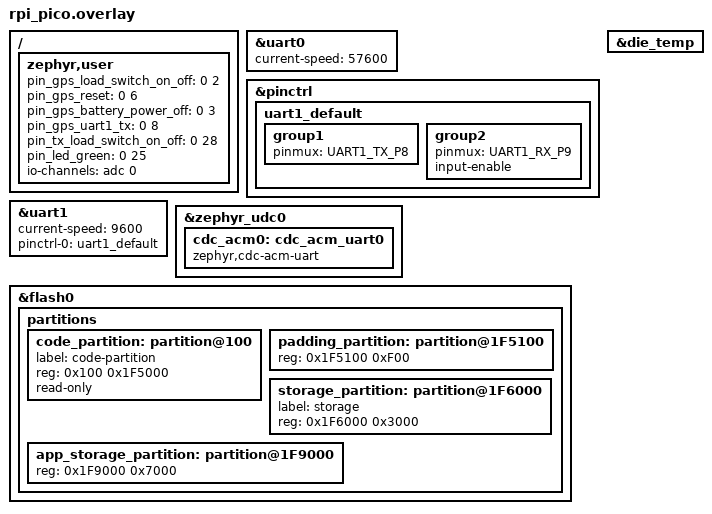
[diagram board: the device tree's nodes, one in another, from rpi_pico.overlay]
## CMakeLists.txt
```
cmake_minimum_required(VERSION 3.13)

# Locate LibPico and pull in initial cmake work
set(LIB_PICO "${CMAKE_CURRENT_SOURCE_DIR}/../../lib")
include(${LIB_PICO}/cmake.preproject.cmake)

# Primary configuration for this project
set(PROJECT_NAME "Traquito")
set(APP_BUILD_VERSION "2024-03-19 16:04:22")
set(PICO_BOARD_ACTUAL "pico")

# Final cmake work
include(${LIB_PICO}/cmake.app.after.cmake)
```

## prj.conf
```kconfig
#####################################################################
# set up project to use c++17 and useful libs/stl
#####################################################################
CONFIG_CPP=y
CONFIG_REQUIRES_FULL_LIBCPP=y
CONFIG_CPP_MAIN=y
CONFIG_STD_CPP20=y
CONFIG_NEWLIB_LIBC_FLOAT_PRINTF=y
CONFIG_CBPRINTF_FP_SUPPORT=y


#####################################################################
# maximum debugging - my code, kernel, everything
#####################################################################
CONFIG_DEBUG_OPTIMIZATIONS=y
CONFIG_DEBUG=y
CONFIG_DEBUG_THREAD_INFO=y
CONFIG_EXCEPTION_STACK_TRACE=y
CONFIG_DEBUG_INFO=y


#####################################################################
# Power Management
#####################################################################


# enabled by default but let's be explicit
# CONFIG_PM=y

# collect stats for this module
# CONFIG_PM_STATS=y

# enable using device driver hooks to be called when
# going in to or out of suspend
# CONFIG_PM_DEVICE=y
# allow individual devices to be suspended/resumed regardless
# of the rest of the system state
# CONFIG_PM_DEVICE_RUNTIME=y
# use the preferred method of managing power, it is handled
# continuously by components close to the resources and
# who are power aware.  resources are meant to be kept
# in the lowest appropriate power state such that
# when a pm_system_suspend() is invoked, it is performed
# more quickly
# CONFIG_PM_DEVICE_RUNTIME_EXCLUSIVE=n



# Allow custom hooks to decide policy each idle period (PowerManager)
# Uncommenting this, and the CMakeLists including Power Manager gets
# the tests going again, but moving on for now.
# CONFIG_PM_POLICY_CUSTOM=y



#####################################################################
# PICO specific HWINFO
#####################################################################

# https://github.com/zephyrproject-rtos/zephyr/pull/54290
# https://github.com/zephyrproject-rtos/zephyr/commit/480ff022bde2d450372bf5339f5ed06453ff9176

# seemingly not ready yet, so commenting out for now

# CONFIG_RP2_BINARY_INFO=y

# CONFIG_RP2_BINARY_INFO_RP_PROGRAM_NAME_OVERRIDE=y
# CONFIG_RP2_BINARY_INFO_RP_PROGRAM_NAME="Traquito"

# CONFIG_RP2_BINARY_INFO_RP_PROGRAM_DESCRIPTION_OVERRIDE=y
# CONFIG_RP2_BINARY_INFO_RP_PROGRAM_DESCRIPTION="Traquito"

# CONFIG_RP2_BINARY_INFO_RP_PROGRAM_URL_OVERRIDE=y
# CONFIG_RP2_BINARY_INFO_RP_PROGRAM_URL="https://traquito.github.io"


#####################################################################
# PICO features
#####################################################################

CONFIG_RPI_PICO_TEMP=y


#####################################################################
# kernel features
#####################################################################

# kernel pipes
CONFIG_PIPES=y


#####################################################################
# main thread
#####################################################################

CONFIG_MAIN_STACK_SIZE=4096


#####################################################################
# system features
#####################################################################

# Enable rebooting by code
CONFIG_REBOOT=y

# monitor high-water mark on stack by placing known-values in stack
# buffer before running
CONFIG_INIT_STACKS=y

# support random number generation
CONFIG_ENTROPY_GENERATOR=y

# Support checking the temperature
CONFIG_SENSOR=y

# Enable I2C/TWI
# https://docs.zephyrproject.org/latest/hardware/peripherals/i2c.html
CONFIG_I2C=y


# watchdog control
CONFIG_WATCHDOG=y
CONFIG_WDT_DISABLE_AT_BOOT=y


# enable access to flash storage
CONFIG_FLASH=y
CONFIG_FLASH_PAGE_LAYOUT=y
CONFIG_NVS=y
CONFIG_MPU_ALLOW_FLASH_WRITE=y


# ADC
CONFIG_ADC=y

# enable stats collection per-module
CONFIG_STATS=y


CONFIG_HWINFO=y

#####################################################################
# Set up interfacing
#####################################################################

# no startup banner
CONFIG_BOOT_BANNER=n

# I want serial enabled in general
CONFIG_SERIAL=y
CONFIG_UART_INTERRUPT_DRIVEN=y
CONFIG_UART_LINE_CTRL=y

# I want logging to function
CONFIG_LOG=y

# I want to use the serial interface for logging
# but when I enable shell, this makes printf'd material come out twice,
# once normally, and another time with the shell prefix.
# so I'm disabling it for now.
CONFIG_LOG_BACKEND_UART=y
CONFIG_LOG_BACKEND_SWO=n

# I want synchronous logging (no queue and print later)
CONFIG_LOG_MODE_IMMEDIATE=y

# I want to be able to influnce what gets logged at runtime (via shell)
CONFIG_LOG_RUNTIME_FILTERING=y

# I want the default to be that every module prints all levels
# 0 = off
# 1 = error
# 2 = error and warning
# 3 = error and warning and info
# 4 = error and warning and info and debug
CONFIG_LOG_DEFAULT_LEVEL=3

# show function name in output
CONFIG_LOG_FUNC_NAME_PREFIX_ERR=y
CONFIG_LOG_FUNC_NAME_PREFIX_WRN=y
CONFIG_LOG_FUNC_NAME_PREFIX_INF=y
CONFIG_LOG_FUNC_NAME_PREFIX_DBG=y

# color it
CONFIG_LOG_BACKEND_SHOW_COLOR=y

# redirect printk to the log
# I am disabling this, because when shell enabled, prink output was
# prefixed with shell.  now I see it on serial with no prefix.
#CONFIG_LOG_PRINTK=y



# ##### Shell #####

# # I want the shell interface to operate
CONFIG_SHELL=y




#####################################################################
# set up stats
#####################################################################
CONFIG_THREAD_RUNTIME_STATS=y




#####################################################################
# set up pwm
#####################################################################
CONFIG_PWM=y


#####################################################################
# set up usb
#####################################################################

CONFIG_USB_DEVICE_DRIVER=y
CONFIG_USB_DEVICE_STACK=y

#
# USB Device Identification
#
CONFIG_USB_DEVICE_SN="0123456789ABCDEF"
CONFIG_USB_DEVICE_VID=0x2FE3
CONFIG_USB_DEVICE_PID=0x0008
CONFIG_USB_DEVICE_MANUFACTURER="Traquito"
CONFIG_USB_DEVICE_PRODUCT="Traquito"

#
# Serial via USB
#
CONFIG_USB_CDC_ACM=y
# makes windows 7 work
CONFIG_CDC_ACM_IAD=y

# use this instead?  NRFX was 2048, this defaults to 1024
# CONFIG_USB_WORKQUEUE_STACK_SIZE=








# CONFIG_USB_MASS_STORAGE=y
# # must be 8 chars
# CONFIG_MASS_STORAGE_INQ_VENDOR_ID="ABCDEFGH"
# # must be 16 chars
# CONFIG_MASS_STORAGE_INQ_PRODUCT_ID="0123456789ABCDEF"
# CONFIG_MASS_STORAGE_STACK_SIZE=2048


# CONFIG_DISK_DRIVER_RAM=y
# CONFIG_FILE_SYSTEM=y
# CONFIG_FAT_FILESYSTEM_ELM=y
# CONFIG_DISK_RAM_VOLUME_SIZE=2



# CONFIG_DISK_ACCESS=y
# CONFIG_DISK_DRIVERS=y
# CONFIG_FS_FATFS_READ_ONLY=n
# CONFIG_FS_FATFS_MOUNT_MKFS=y

# CONFIG_NRF_APPROTECT_LOCK=
# CONFIG_NRF_APPROTECT_USE_UICR=
# CONFIG_NRF_APPROTECT_USER_HANDLING=


#####################################################################
# set up disk
#####################################################################

# CONFIG_DISK_ACCESS=y
# CONFIG_DISK_DRIVERS=y


# CONFIG_FLASH=y
# CONFIG_DISK_DRIVER_FLASH=y


# CONFIG_FLASH_MAP=y
# CONFIG_FLASH_PAGE_LAYOUT=y
# CONFIG_MPU_ALLOW_FLASH_WRITE=y


# CONFIG_FILE_SYSTEM=y
# CONFIG_FAT_FILESYSTEM_ELM=y
# CONFIG_FS_FATFS_READ_ONLY=n
# CONFIG_FS_FATFS_MOUNT_MKFS=y




# #####################################################################
# # set multi-protocol service layer (multiple radio protocol support)
# #####################################################################
# # enable multi-protocol service layer (doesn't work with CONFIG_BT_LL_SW_SPLIT seemingly)
# CONFIG_MPSL=y
# # max sessions MPSL will support
# # 1 for BLE
# # 1 for ESB
# # 2 for MPSL shell testing
# # 1 for ESB shell testing
# CONFIG_MPSL_TIMESLOT_SESSION_COUNT=5
# # let's see during dev
# CONFIG_MPSL_LOG_LEVEL_DBG=y
# # allow myself to catch assert errors in my own code (and still die)
# CONFIG_MPSL_ASSERT_HANDLER=y






#####################################################################
# set up ble
#####################################################################
# CONFIG_SYSTEM_WORKQUEUE_STACK_SIZE=2048
# CONFIG_BT_RX_STACK_SIZE=4096
# CONFIG_MAIN_STACK_SIZE=6114
# CONFIG_BT=y
# CONFIG_BT_HCI=y
# CONFIG_BT_CTLR=y
# # Use the zephyr BLE implementation instead of the SoftDevice from Nordic
# # CONFIG_BT_LL_SW_SPLIT=y


# # use extended advertising
# CONFIG_BT_EXT_ADV=y
# # support this many advertising sets
# CONFIG_BT_EXT_ADV_MAX_ADV_SET=4


# CONFIG_BT_PERIPHERAL=y
# CONFIG_BT_CENTRAL=y
# CONFIG_BT_BROADCASTER=y
# CONFIG_BT_OBSERVER=y

# # Enable Security Manager Protocol (SMP), making it possible to pair devices over LE
# CONFIG_BT_SMP=y

# # allow me to set the code to show to users on their device via bt_passkey_set()
# CONFIG_BT_FIXED_PASSKEY=y

# # let me see more details about the other side of the connection
# CONFIG_BT_REMOTE_INFO=y

# # let me change and see changes to the PHY layer
# CONFIG_BT_USER_PHY_UPDATE=y

# # let me change and see changes to the data length (MTU?)
# CONFIG_BT_USER_DATA_LEN_UPDATE=y

# # let me express preferences for phy modulation
# CONFIG_BT_CTLR_PHY_CODED=y
# # CONFIG_BT_HCI_VS_EXT=y
# # CONFIG_BT_PHY_UPDATE=y

# # let me change (my) and measure (their) transmit power levels
# CONFIG_BT_CTLR_CONN_RSSI=y
# # CONFIG_BT_CTLR_ADVANCED_FEATURES=y    ; # triggers warning, needed?
# CONFIG_BT_CTLR_TX_PWR_DYNAMIC_CONTROL=y
# # ?
# # CONFIG_BT_TPS=y



# #####################################################################
# # set up ESB (extended shock burst)
# #####################################################################
# CONFIG_ESB=y
# CONFIG_NCS_SAMPLES_DEFAULTS=y
# CONFIG_ESB_MAX_PAYLOAD_LENGTH=252
# CONFIG_ESB_RX_FIFO_SIZE=1
# CONFIG_ESB_TX_FIFO_SIZE=1



# fat frames
# https://devzone.nordicsemi.com/f/nordic-q-a/84226/increasing-ble-mtu-data-length-for-notifications-on-ncs-v1-8
# https://github.com/zephyrproject-rtos/zephyr/issues/25648
# Uncoded LE Data Packet Format:
#
# | Preamble | Access  |                           PDU (2 to 257 bytes)                         |   CRC   |
# |          | Address | LL Header |       Link Layer PDU (0 to 251 bytes)           |    MIC   |         |
# |          |         |           | L2CAP Header |      L2CAP PDU (0-247 bytes)     | Optional |         |
# |          |         |           |              |    ATT Header    |  ATT Payload  |          |         |
# |          |         |           |              | OpCode | Handle  |               |          |         |
# |  1 byte  | 4 bytes |  2 bytes  |   4 bytes    | 1 byte | 2 bytes | 0 - 244 bytes | 4 bytes  | 3 bytes |
#
# L2CAP can be larger than 247 bytes, but will be split across multiple LL packets as a result.
# ATT payloads can be larger than 244 bytes, but will be split across multiple LL packets as a result.
# 
#
# Kconfig Symbols:
#     CONFIG_BT_CTLR_DATA_LENGTH_MAX : Maximum payload size of the Link Layer PDU
#     CONFIG_BT_BUF_ACL_TX_SIZE      : Maximum L2CAP PDU is limited to this value - 4
#     CONFIG_BT_BUF_ACL_RX_SIZE      : Maximum L2CAP PDU is limited to this value - 4
#     CONFIG_BT_L2CAP_TX_MTU         : Maximum L2CAP PDU size for transmission
# CONFIG_BT_BUF_ACL_RX_SIZE=251
# CONFIG_BT_BUF_ACL_TX_SIZE=251
# CONFIG_BT_L2CAP_TX_MTU=247
# CONFIG_BT_CTLR_DATA_LENGTH_MAX=251
# # CONFIG_BT_GATT_AUTO_UPDATE_MTU=


# CONFIG_BT_GATT_DYNAMIC_DB=y
# CONFIG_BT_DEVICE_APPEARANCE_DYNAMIC=y
# CONFIG_BT_DEVICE_NAME_DYNAMIC=y


# # unsure these
# #CONFIG_BT_EXT_ADV=y


# # settings subsystem required as well for bluetooth libs (for bonding)
# CONFIG_BT_SETTINGS=y
# CONFIG_FLASH=y
# CONFIG_FLASH_PAGE_LAYOUT=y
# CONFIG_FLASH_MAP=y
# CONFIG_NVS=y
# CONFIG_SETTINGS=y

# # major memory hog, ~2k per connection (wtf)
# CONFIG_BT_MAX_CONN=20


#####################################################################
# allow access to flash for read/write (non-volatile memory store)
#####################################################################

# CONFIG_MPU_ALLOW_FLASH_WRITE=y

# CONFIG_FLASH=y
# CONFIG_FLASH_MAP=y
# CONFIG_FLASH_PAGE_LAYOUT=y

# CONFIG_FILE_SYSTEM=y
# CONFIG_FILE_SYSTEM_LITTLEFS=y
```

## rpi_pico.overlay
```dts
/////////////////////////////////////////////////////////////////////
// App-specific settings
/////////////////////////////////////////////////////////////////////

/ {
    zephyr,user {
        pin_gps_load_switch_on_off = <0 2>;
        pin_gps_reset              = <0 6>;
        pin_gps_battery_power_off  = <0 3>;
        pin_gps_uart1_tx           = <0 8>;

        pin_tx_load_switch_on_off = <0 28>;
        
        pin_led_green = <0 25>;
    };
};



/////////////////////////////////////////////////////////////////////
// UART0
/////////////////////////////////////////////////////////////////////

&uart0 {
    // current-speed = <76800>;    // 48MHz handles it no prob
    current-speed = <57600>;    // 48MHz handles it no prob, probably higher too
    // current-speed = <38400>;    // 12MHz can not handle it
    // current-speed = <19200>;    // 12MHz can not handle it
    // current-speed = <9600>;
};




/////////////////////////////////////////////////////////////////////
// UART1
/////////////////////////////////////////////////////////////////////

&pinctrl {
	uart1_default: uart1_default {
		group1 {
			pinmux = <UART1_TX_P8>;
		};
		group2 {
            pinmux = <UART1_RX_P9>;
			input-enable;
		};
	};
};

&uart1 {
    current-speed = <9600>;
	status = "okay";
	pinctrl-0 = <&uart1_default>;
	pinctrl-names = "default";
};


/////////////////////////////////////////////////////////////////////
// UART USB
/////////////////////////////////////////////////////////////////////

&zephyr_udc0 {
    cdc_acm0: cdc_acm_uart0 {
        compatible = "zephyr,cdc-acm-uart";
	};
};


/////////////////////////////////////////////////////////////////////
// ADC
/////////////////////////////////////////////////////////////////////

// ADC already enabled on all 4 channels
// CH0 = GP26
// CH1 = GP27
// CH2 = GP28
// CH3 = GP29       // VSYS/3
// CH4 = <internal> // temperature sensor

/ {
	zephyr,user {
		io-channels = <&adc 0>;
	};
};



/////////////////////////////////////////////////////////////////////
// Temperature sensor (internal)
/////////////////////////////////////////////////////////////////////

&die_temp {
    status = "okay";
};

/////////////////////////////////////////////////////////////////////
// Flash Partitions
/////////////////////////////////////////////////////////////////////

/delete-node/ &code_partition;

&flash0 {
	partitions {
        // we want to reserve space for the zerphyr-convention of a "storage"
        // partition existing, since a number of zephyr libs beyond my control
        // expect it to exist.
        //
        // we also want to have app-specific storage.
        //
        // the storage partition should be 8192 bytes
        // on nordic this was 3 pages, not sure yet on pico
        //
        // the app storage partition should be 24,576 bytes
        // on noridc this was 7 pages, not sure yet on pico

        // we will have to override the pico-defined size of the
        // code partition.
        // 
        // on nordic, the flash pages were on 0x1000 boundaries.
        // that may not be the case here.  but since we have a ton
        // of storage, I'll play it safe and have a gap fill between
        // the code and the partition so they align to the 0x1000
        // boundaries

        // calculations:
        // https://docs.google.com/spreadsheets/d/1JafSN7NNXzIZdNnoIFAYexfTvMJzwK_n4mVGBEJF45I/edit#gid=0

		code_partition: partition@100 {
			label = "code-partition";
			reg = <0x100 0x1F5000>;
			read-only;
		};
        
		padding_partition: partition@1F5100 {
            reg = <0x1F5100 0xF00>;
            /delete-property/ read-only;
		};
        
		storage_partition: partition@1F6000 {
            label = "storage";
			reg = <0x1F6000 0x3000>;
            /delete-property/ read-only;
		};
        
		app_storage_partition: partition@1F9000 {
            reg = <0x1F9000 0x7000>;
            /delete-property/ read-only;
		};
	};
};
```

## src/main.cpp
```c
#include "Application.h"


int main()
{
    Application app;

    app.Run();

    return 0;
}
```

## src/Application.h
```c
#pragma once

#include <algorithm>
using namespace std;

#include "App.h"

#include "SubsystemGps.h"
#include "SubsystemTx.h"

#include "JSONMsgRouter.h"
#include "TempSensorInternal.h"
#include "USB.h"

#include "RP2040.h"



struct TestConfiguration
{
    bool enabled = false;

    bool watchdogOn = true;
    bool logAsync = true;
    bool evmOnly = false;
    bool sendEncoded = true;
    bool apiMode = false;
};

TestConfiguration testCfg;


// special convenience setting to switch to separately-released build
static const bool API_MODE_BUILD = false;


// 1ms instead of 700ms of high initial current
// lower speed w/ usb couldn't keep up
inline static int Init()
{
    // 12mA baseline
    RP2040::Clock::SetClock48MHzNew();

    if (testCfg.enabled)
    {
        RP2040::Clock::PrintAll();
    }

    // saves 5mA at 125MHz
    // saves 2mA at  48MHz
    RP2040::Peripheral::DisablePeripheralList({
        RP2040::Peripheral::SPI1,
        RP2040::Peripheral::SPI0,
        RP2040::Peripheral::PWM,
        RP2040::Peripheral::PIO1,
        RP2040::Peripheral::PIO0,
        RP2040::Peripheral::I2C1,
    });

    return 1;
}

#include <zephyr/init.h>
SYS_INIT(Init, APPLICATION, 1);


class Application
: public App
{
public:

    Application()
    {
        ReadDeviceTree();

        // override for special build
        testCfg = !API_MODE_BUILD ? testCfg : TestConfiguration{
            .enabled = true,
            .apiMode = true,
        };
    }

    /////////////////////////////////////////////////////////////////
    // Program start - Decide Configuration or Flight Mode
    /////////////////////////////////////////////////////////////////

    void Run()
    {
        Timeline::Global().Event("Application");

        LogNL(2);
        Log("Module Details");
        Log("Software: ", Version::GetVersionShort());
        LogNL();

        // Watchdog setup
        if (testCfg.enabled == false || (testCfg.enabled && testCfg.watchdogOn == true))
        {
            Watchdog::SetTimeout(5'000);
            Watchdog::Start();
            Log("Watchdog enabled");

            tedWatchdog_.SetCallback([]{
                Watchdog::Feed();
            }, "TIMER_WATCHDOG_FEED");
            tedWatchdog_.RegisterForTimedEventIntervalRigid(2'000, 0);
        }

        // set up blinker
        blinker_.SetPin(pinLedGreen_);

        // Initial blink pattern indicates testing of systems and the
        // sufficiency of the power source (ie solar).

        // Blink 1 - CPU can run on this power
        PAL.Delay(1'000);
        blinker_.Blink(1, 500, 100);
        Watchdog::Feed();

        // Blink 2 - GPS can run on this power
        ssGps_.ModulePowerOnBatteryOn();
        // PAL.Delay(500);  // the power on has a delay of 500 in it already
        PAL.Delay(500);  // add another 500 for a total of 1 sec
        blinker_.Blink(1, 500, 100);
        ssGps_.ModulePowerOff();
        Watchdog::Feed();

        // Blink 3 - Transmitter can run on this power
        ssTx_.Enable();
        ssTx_.RadioOn();
        PAL.Delay(1'000);
        blinker_.Blink(1, 500, 100);
        ssTx_.RadioOff();
        ssTx_.Disable();
        Watchdog::Feed();

        Log("Power test blinking sequence complete");

        // Set up system elements common between modes
        SetupShell();
        SetupJSON();

        if (testCfg.enabled && testCfg.logAsync == false)
        {
            Evm::DisableAutoLogAsync();
            Log("Async logging disabled");
        }

        // Set TX watchdog feeders that also keep the blink going
        ssTx_.SetCallbackOnTxStart([this]{
            Watchdog::Feed();
            blinker_.On();
        });
        ssTx_.SetCallbackOnBitChange([this]{
            Watchdog::Feed();
            blinker_.Toggle();
        });
        ssTx_.SetCallbackOnTxEnd([this]{
            Watchdog::Feed();
            BlinkerIdle();
        });

        // Determine mode of operation
        bool configurationMode = false;
        if (testCfg.enabled == false)
        {
            USB::SetCallbackConnected([&]{
                configurationMode = true;
            });
            USB::SetCallbackDisconnected([]{
                LogModeSync();
                Log("USB DISCONNECTED");
                LogModeAsync();
                PAL.Reset();
            });
        }
        USB::Enable();

        Log("Determining startup mode");
        LogNL();
        Evm::MainLoopRunFor(1'000);

        if (testCfg.enabled && testCfg.evmOnly)
        {
            BlinkerIdle();
            LogNL(2);
            Log("Main Loop Only");
            Evm::MainLoop();
        }

        bool cfgModeEnableBlink = true;
        if (testCfg.enabled)
        {
            // normally the testmode being enabled means you want
            // to test sending messages in flight mode.
            // however, the api mode override lets you enter
            // configuration mode instead
            if (testCfg.apiMode == true)
            {
                Log("API Mode Enabled");
                configurationMode = true;
                cfgModeEnableBlink = false;
            }
            else
            {
                configurationMode = false;
            }
        }
        
        if (configurationMode)
        {
            ConfigurationMode(cfgModeEnableBlink);
        }
        else
        {
            FlightMode();
        }

        // now that mode is established, if you subsequently plug back
        // into USB the device should restart to re-evaluate.
        // In API mode no such switch happens, the devices runs without
        // interruption
        if (testCfg.enabled == false ||
           (testCfg.enabled && testCfg.apiMode == false))
        {
            USB::SetCallbackConnected([&]{
                LogModeSync();
                Log("USB Connected");
                LogModeAsync();
                PAL.Reset();
            });
        }

        // Handle events
        Evm::MainLoop();
    }

    /////////////////////////////////////////////////////////////////
    // Configuration Mode
    /////////////////////////////////////////////////////////////////

    void ConfigurationMode(bool enableBlink = true)
    {
        Log("Configuration Mode");

        ssGps_.EnableConfigurationMode();

        // announce the temperature regularly
        static TimedEventHandlerDelegate tedTemp;
        tedTemp.SetCallback([this]{
            JSONMsgRouter::Send([&](const auto &out){
                out["type"] = "TEMP";
                out["tempC"] = tempSensor_.GetTempC();
                out["tempF"] = tempSensor_.GetTempF();
            });
        }, "APP_TEMP_TIMER");
        tedTemp.RegisterForTimedEventIntervalRigid(1000, 0);

        if (enableBlink)
        {
            // Set on async blinking journey
            BlinkerIdle();
        }
    }



    /////////////////////////////////////////////////////////////////
    // Flight Mode
    /////////////////////////////////////////////////////////////////
    
    void FlightMode()
    {
        LogNL();
        LogNL();
        Log("Flight Mode");
        LogNL();

        if (testCfg.enabled)
        {
            // testing - fudge some configuration
            Configuration &txCfg = ssTx_.GetConfiguration();
            txCfg.band = "20m";
            txCfg.callsign = "KD2KDD";
            txCfg.channel = 414;
            txCfg.correction = 0;
            txCfg.Put();
            txCfg.Get();
        }

        // Load flight configuration -- ensure it exists
        if (ssTx_.ReadyToFly() == false)
        {
            Log("ERR: ==== NOT READY TO FLY - FATAL ====");

            // panic blink - let watchdog kill
            while (true)
            {
                BlinkerBlinkOncePanic();
            }
        }
        else
        {
            ssTx_.SetupTransmitterForFlight();

            Configuration &txCfg = ssTx_.GetConfiguration();
            auto cd = WSPR::GetChannelDetails(txCfg.band, txCfg.channel);

            Log("==== Ok to fly! ====");
            Log("Callsign  : ", txCfg.callsign);
            Log("Band      : ", txCfg.band);
            Log("Channel   : ", txCfg.channel);
            Log("ID13      : ", cd.id13);
            Log("Min       : ", cd.min);
            Log("Lane      : ", cd.lane);
            Log("Freq      : ", Commas(cd.freq));
            Log("Correction: ", txCfg.correction);
            LogNL();

            // Signal ok
            blinker_.Blink(4, 100, 100);

            // give visual space to distinguish these "ok" blinks from
            // upcoming status blinks
            Watchdog::Feed();
            PAL.Delay(1'500);
        }

        // Go to initial state
        OnNoTimeNoFix();
    }

    /////////////////////////////////////////////////////////////////
    // Flight Mode Async Loop
    /////////////////////////////////////////////////////////////////

    void OnNoTimeNoFix()
    {
        t_.Reset();
        t_.SetMaxEvents(50);
        t_.Event("NO_TIME_NO_FIX");

        // ask gps to get a fix
        if (testCfg.enabled == false)
        {
            ssGps_.DisableVerboseLogging();
        }
        ssGps_.EnableFlightMode();
        t_.Event("GpsEnabled");
        Log("Requesting Fix 3DPlus");
        ssGps_.RequestNewFix3DPlus([this](const Fix3DPlus &fix){
            t_.Event("Fix3DPlus");

            // cancel timer
            CancelGpsLockOrDieTimer();

            // capture fix
            fix_ = fix;

            // shut off gps
            ssGps_.Disable();

            // go to next state
            OnYesTimeYesFix_Early();
        });
        t_.Event("FixRequested");
        StartGpsLockOrDieTimer();

        BlinkerGpsSearch();
    }

    void OnYesTimeYesFix_Early()
    {
        t_.Event("YES_TIME_YES_FIX__EARLY");

        // figure out when to wake up to send this fix
        const Configuration &txCfg = ssTx_.GetConfiguration();
        WSPR::ChannelDetails cd = WSPR::GetChannelDetails(txCfg.band, txCfg.channel);

        uint8_t fixMinute = fix_.minute % 10;

        if (testCfg.enabled)
        {
            // pick the next 2 min slot
            cd.min = (fixMinute + (fixMinute % 2 ? 1 : 2)) % 10;
        }

        // determine minutes duration before target minute
        uint8_t minBefore;
        if (fixMinute < cd.min)
        {
            minBefore = cd.min - fixMinute;
        }
        else if (fixMinute == cd.min)
        {
            // only if we're literally on exactly the moment, then
            // you can say zero time remaining.
            // otherwise, the logic below will subtract time (from zero)
            // and end up with a very long delay (which crashes the system)
            if (fix_.second == 0 && fix_.millisecond == 0)
            {
                minBefore = 0;
            }
            else
            {
                minBefore = 10;
            }
        }
        else // fixMinute > cd.min
        {
            // move forward to the next 10 minute cycle
            // eg this is minute 8, I target minute 6
            // 8 - 6 = 2
            // 10 - 2 = 8; therefore I wait 8 minutes
            // 8 minutes after the minute 8 is the 6th minute, that's my target
            minBefore = (10 - (fixMinute - cd.min));
        }

        // calculate ms difference
        uint32_t delayTransmitMs = minBefore * 60 * 1'000;

        // give credit for how far into this minute we are already
        delayTransmitMs -= (fix_.second * 1'000);
        delayTransmitMs -= fix_.millisecond;

        // and actually supposed to be at :01, so add a little fudge
        // factor in there, tuned emperically.
        // (we're late in our timing anyway so don't overdo it)
        static const uint32_t FUDGE_MS = 410;
        delayTransmitMs += FUDGE_MS;

        // to avoid TX drift, we want to turn the radio on a while before sending
        static const uint32_t RADIO_ON_EARLY_TARGET_MS = 30'000;
        uint32_t delayRadioOnMs;
        if (delayTransmitMs >= RADIO_ON_EARLY_TARGET_MS)
        {
            delayRadioOnMs = delayTransmitMs - RADIO_ON_EARLY_TARGET_MS;
        }
        else if (delayTransmitMs < RADIO_ON_EARLY_TARGET_MS)
        {
            delayRadioOnMs = 0;
        }

        uint64_t timeNow = PAL.Millis();

        // set timer for radio on
        tedRadioOn_.SetCallback([this]{
            // bring transmitter online
            t_.Event("Transmitter Starting");

            Log("Radio warmup starting");
            Log("RTC Now: ", MsToMinutesStr(PAL.Millis()));

            ssTx_.Enable();
            ssTx_.RadioOn();
            ssTx_.SetupTransmitterForFlight();

            BlinkerTransmit();

            t_.Event("Transmitter Online");
        }, "TIMER_APP_RADIO_ON");
        tedRadioOn_.RegisterForTimedEvent(delayRadioOnMs);

        // set timer for TX
        tedSend_.SetCallback([this]{
            OnYesTimeYesFix_TimeToSend();
        }, "TIMER_APP_TX");
        tedSend_.RegisterForTimedEvent(delayTransmitMs);


        // do some logging to explain the schedule
        uint32_t fixTimeAsMs     = (fix_.minute * 60 * 1'000) + (fix_.second * 1'000) + fix_.millisecond;
        uint32_t radioOnTimeAsMs = fixTimeAsMs + delayRadioOnMs;
        uint32_t txTimeAsMs      = fixTimeAsMs + delayTransmitMs;

        string timeGpsNow                = MsToMinutesStr(fixTimeAsMs);
        string timeRadioOn               = MsToMinutesStr(radioOnTimeAsMs);
        string timeRadioOnDuration       = MsToMinutesStr(delayRadioOnMs);
        string durationRadioOnEarly      = MsToMinutesStr(delayTransmitMs - delayRadioOnMs);
        string durationRadioDelayWanted  = MsToMinutesStr(RADIO_ON_EARLY_TARGET_MS);
        string timeTx                    = MsToMinutesStr(txTimeAsMs);
        string timeTxDuration            = MsToMinutesStr(delayTransmitMs);

        LogNL();
        Log("Scheduling TX to GPS time");
        LogNL();
        Log("GPS Now  : ", timeGpsNow);
        Log("  Radio  : ", timeRadioOn, " (", timeRadioOnDuration, " from now, ", durationRadioOnEarly, " early, wanted ", durationRadioDelayWanted, ")");
        Log("  TX     : ", timeTx,      " (", timeTxDuration,      " from now)");
        Log("  Target : _", cd.min, ":00." + to_string(FUDGE_MS));
        LogNL();
        Log("RTC Now      : ", MsToMinutesStr(timeNow));
        Log("  Radio on at: ", MsToMinutesStr(timeNow + delayRadioOnMs));
        Log("  TX    on at: ", MsToMinutesStr(timeNow + delayTransmitMs));
        LogNL();

        t_.Event("Scheduled");

        BlinkerIdle();
    }

    void OnYesTimeYesFix_TimeToSend()
    {
        t_.Event("YES_TIME_YES_FIX__TIME_TO_SEND");

        Log("Regular message sending start");
        Log("RTC Now: ", MsToMinutesStr(PAL.Millis()));

        // retrieve flight configuration
        const Configuration &txCfg = ssTx_.GetConfiguration();

        // take note of the time the sending of the regular message begins
        uint64_t timeSendRegular = PAL.Millis();

        // send regular message
        static const uint8_t POWER_DBM = 13;
        ssTx_.SendRegularMessage(txCfg.callsign, fix_.maidenheadGrid.substr(0, 4), POWER_DBM);
        LogNL();

        t_.Event("Regular Message Sent");

        if (testCfg.enabled && testCfg.sendEncoded == false)
        {
            Timeline::Global().Report();
            BlinkerIdle();

            LogNL();
            Log("Not sending encoded message");
            LogNL();

            OnYesTimeNoFix();
            return;
        }

        // purposefully do not turn the radio off, the longer it
        // runs the more stable the frequency (less drift)

        // delay to send the U4B message
        uint64_t timeSinceRegular = PAL.Millis() - timeSendRegular;
        const uint32_t EXPECTED_DELAY_START_REGULAR_TO_START_U4B = 2 * 60 * 1'000;    // 2 min

        uint32_t delayToU4bMs = 0;
        if (timeSinceRegular < EXPECTED_DELAY_START_REGULAR_TO_START_U4B)
        {
            delayToU4bMs = EXPECTED_DELAY_START_REGULAR_TO_START_U4B - timeSinceRegular;
        }

        // feed watchdog while waiting
        while (delayToU4bMs)
        {
            Watchdog::Feed();

            uint32_t delayMs = min(WSPR_BIT_DURATION_MS, delayToU4bMs);
            blinker_.Toggle();
            PAL.DelayBusy(delayMs);

            delayToU4bMs -= delayMs;
        }
        Watchdog::Feed();

        t_.Event("Waited for U4B Send Time");

        Log("Encoded message sending start");
        Log("RTC Now: ", MsToMinutesStr(PAL.Millis()));

        // get data needed to fill out encoded message
        WSPR::ChannelDetails cd = WSPR::GetChannelDetails(txCfg.band, txCfg.channel);

        string   grid56    = fix_.maidenheadGrid.substr(4, 2);
        uint32_t altM      = fix_.altitudeM < 0 ? 0 : fix_.altitudeM;
        int8_t   tempC     = tempSensor_.GetTempC();
        double   voltage   = PAL.MeasureVCC();  // capture under max load
        bool     gpsValid  = true;

        ssTx_.SendEncodedMessage(
            cd.id13,
            grid56,
            altM,
            tempC,
            voltage,
            fix_.speedKnots,
            gpsValid
        );
        LogNL();

        t_.Event("U4B Message Sent");

        // bring transmitter offline
        ssTx_.RadioOff();
        ssTx_.Disable();

        t_.Event("Transmitter Offline");
        t_.ReportNow();

        BlinkerIdle();

        // get the next fix
        OnYesTimeNoFix();
    }

    void OnYesTimeNoFix()
    {
        // need a fix, get one

        // this is equivalent
        OnNoTimeNoFix();
    }


    /////////////////////////////////////////////////////////////////
    // GPS Lock Or Die timer
    /////////////////////////////////////////////////////////////////
    
    void StartGpsLockOrDieTimer()
    {
        static const uint32_t TWENTY_MINUTES = 20 * 60 * 1'000;

        tedGpsLockOrDie_.SetCallback([this]{
            LogModeSync();

            LogNL();
            Log("No GPS Lock within ", MsToMinutesStr(TWENTY_MINUTES));

            // hard reset GPS
            Log("Hard Resetting GPS");
            ssGps_.ModuleHardReset();

            // reboot via watchdog kill
            Log("Rebooting via Watchdog death");
            while (true)
            {
                BlinkerBlinkOncePanic();
            }
        }, "TIMER_GPS_LOCK_OR_DIE");
        tedGpsLockOrDie_.RegisterForTimedEvent(TWENTY_MINUTES);
    }

    void CancelGpsLockOrDieTimer()
    {
        tedGpsLockOrDie_.DeRegisterForTimedEvent();
    }


    /////////////////////////////////////////////////////////////////
    // Flight Mode - Blinker states
    /////////////////////////////////////////////////////////////////

    inline static const uint32_t WSPR_BIT_DURATION_MS = 683;

    // once every 5 seconds
    void BlinkerIdle()
    {
        blinker_.SetBlinkOnOffTime(75, 4925);
        blinker_.EnableAsyncBlink();
    }

    // once every 1 seconds
    void BlinkerGpsSearch()
    {
        blinker_.SetBlinkOnOffTime(75, 925);
        blinker_.EnableAsyncBlink();
    }

    // alternating 683ms periods
    // also operated by hand, but also run during radio warmup
    void BlinkerTransmit()
    {
        blinker_.SetBlinkOnOffTime(WSPR_BIT_DURATION_MS, WSPR_BIT_DURATION_MS);
        blinker_.EnableAsyncBlink();
    }

    void BlinkerBlinkOncePanic()
    {
        blinker_.Blink(1, 40, 40);
    }


private:

    /////////////////////////////////////////////////////////////////
    // Utility
    /////////////////////////////////////////////////////////////////

    // Indicate signs of life during runtime for a period of time
    //
    // Enhancement - Stop this from being high during transmit or GPS
    // to conserve power
    void SetupSignsOfLife(uint32_t durationMsIn)
    {
        static const uint32_t PERIOD_MS = 5000;
        static const uint32_t ON_MS     =   75;
        static const uint32_t OFF_MS    = PERIOD_MS - ON_MS;

        static uint32_t durationMs;
        static uint32_t countRemaining;

        durationMs = durationMsIn;
        countRemaining = durationMs / PERIOD_MS;

        static TimedEventHandlerDelegate tedLed;
        tedLed.SetCallback([this](){
            static uint32_t durationMsNext = OFF_MS;
            durationMsNext = (durationMsNext == ON_MS ? OFF_MS : ON_MS);

            if (countRemaining)
            {
                pinLedGreen_.DigitalToggle();

                tedLed.RegisterForTimedEvent(durationMsNext);
            }
            else
            {
                pinLedGreen_.DigitalWrite(0);
            }

            --countRemaining;
        }, "TIMER_APP_SIGNS_OF_LIFE");

        tedLed.RegisterForTimedEvent(0);
    }


    /////////////////////////////////////////////////////////////////
    // Startup
    /////////////////////////////////////////////////////////////////

    void SetupShell()
    {
        Shell::AddCommand("app.temp", [this](vector<string> argList){
            Log("TempC: ", tempSensor_.GetTempC());
            Log("TempF: ", tempSensor_.GetTempF());
        }, { .argCount = 0, .help = "app get temp"});

        Shell::AddCommand("app.test.led.green.on", [this](vector<string> argList){
            pinLedGreen_.DigitalWrite(1);
        }, { .argCount = 0, .help = ""});

        Shell::AddCommand("app.test.led.green.off", [this](vector<string> argList){
            pinLedGreen_.DigitalWrite(0);
        }, { .argCount = 0, .help = ""});
    }

    void SetupJSON()
    {
        JSONMsgRouter::RegisterHandler("REQ_GET_DEVICE_INFO", [this](auto &in, auto &out){
            out["type"] = "REP_GET_DEVICE_INFO";

            out["swVersion"] = Version::GetVersion();
            if (testCfg.enabled && testCfg.apiMode)
            {
                out["mode"] = "API";
            }
            else
            {
                out["mode"] = "TRACKER";
            }
        });
    }

    void ReadDeviceTree()
    {
        pinLedGreen_ = { DT_GET(pin_led_green) };
    }


private:

    Pin pinLedGreen_;

    SubsystemGps ssGps_;
    SubsystemTx ssTx_;

    Fix3DPlus fix_;

    TimedEventHandlerDelegate tedRadioOn_;
    TimedEventHandlerDelegate tedSend_;
    TimedEventHandlerDelegate tedWatchdog_;
    TimedEventHandlerDelegate tedGpsLockOrDie_;

    Blinker blinker_;

    Timeline t_;

    TempSensorInternal tempSensor_;
};
```

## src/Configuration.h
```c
#pragma once

#include <array>
#include <string>
using namespace std;

#include "Flash.h"
#include "JSONMsgRouter.h"
#include "WSPR.h"


class Configuration
{
private:
    inline static const string DEFAULT_BAND = "20m";

    struct ConfigurationFlashState
    {
        array<char, 5 + 1> bandStorage;
        uint16_t channel;
        array<char, 6 + 1> callsignStorage;
        int32_t correction;
    };

    Flashable<ConfigurationFlashState> flashState_;

    void Reset()
    {
        flashState_.bandStorage.fill(0);
        band = DEFAULT_BAND;

        flashState_.channel = 0;
        channel = 0;

        flashState_.callsignStorage.fill(0);
        callsign = "";

        flashState_.correction = 0;
        correction = 0;
    }

public:
    Configuration()
    {
        Reset();

        // Pull up stored configuration
        bool cfgOk = Get();

        LogNL();
        if (cfgOk == false)
        {
            Log("INF: No saved configuration");
        }
        else
        {
            Log("INF: Restoring saved configuration");
        }

        SetupShell();
        SetupJSON();
    }

    bool Get()
    {
        bool retVal = flashState_.Get();

        // the storage values are a write-through cache.
        // don't read from them unless you know you've written to them first
        if (retVal)
        {
            band       = (const char *)flashState_.bandStorage.data();
            channel    = (uint16_t)flashState_.channel;
            callsign   = (const char *)flashState_.callsignStorage.data();
            correction = flashState_.correction;
        }

        return retVal;
    }

    bool Put()
    {
        flashState_.bandStorage.fill(0);
        band.copy(flashState_.bandStorage.data(), min(band.size(), flashState_.bandStorage.size()));

        flashState_.channel = channel;

        flashState_.callsignStorage.fill(0);
        callsign.copy(flashState_.callsignStorage.data(), min(callsign.size(), flashState_.callsignStorage.size()));

        flashState_.correction = correction;

        return flashState_.Put();
    }


private:

    void SetupShell()
    {
        Shell::AddCommand("app.cfg.del", [this](vector<string> argList){
            flashState_.Delete();
            Reset();

            Log("Configuration Deleted, state reset");
        }, { .argCount = 0, .help = "delete config"});
    }

    void SetupJSON()
    {
        JSONMsgRouter::RegisterHandler("REQ_GET_CONFIG", [this](auto &in, auto &out){
            out["type"] = "REP_GET_CONFIG";

            out["band"]       = band;
            out["channel"]    = channel;
            out["callsign"]   = callsign;
            out["correction"] = correction;

            out["callsignOk"] = WSPR::CallsignIsValid(callsign);
        });

        JSONMsgRouter::RegisterHandler("REQ_SET_CONFIG", [this](auto &in, auto &out){
            out["type"] = "REP_SET_CONFIG";

            string bandIn        = (const char *)in["band"];
            int16_t channelIn    = (int16_t)in["channel"];
            string callsignIn    = (const char *)in["callsign"];
            int32_t correctionIn = (int32_t)in["correction"];

            bool ok = true;
            string err = "";
            string sep = "";

            if (bandIn != WSPR::GetDefaultBandIfNotValid(bandIn))
            {
                ok = false;
                err += sep + "Invalid band";
                sep = ", ";
            }
            
            if (channelIn != WSPR::GetDefaultChannelIfNotValid(channelIn))
            {
                ok = false;
                err += sep + "Invalid channel";
                sep = ", ";
            }

            if (WSPR::CallsignIsValid(callsignIn) == false)
            {
                ok = false;
                err += sep + "Invalid callsign";
                sep = ", ";
            }

            if (ok)
            {
                // attempt to store
                Configuration cfgCache = *this;

                band       = bandIn;
                channel    = channelIn;
                callsign   = callsignIn;
                correction = correctionIn;

                ok = Put();

                if (ok == false)
                {
                    *this = cfgCache;

                    err += sep + "Could not store to flash";
                    sep = ", ";
                }
            }

            Log("REQ_SET_CONFIG: ", bandIn, ", ", channelIn, ", ", callsignIn, ", ", correctionIn);
            Log("OK: ", ok, ", err: \"", err, "\"");
            Log("Current config: ", band, ", ", channel, ", ", callsign, ", ", correction);

            out["ok"] = ok;
            out["err"] = err;
        });
    }

public:

    string   band;
    uint16_t channel;
    string   callsign;
    int32_t correction;
};

inline void LogNNL(const Configuration &c)
{
    Log("{");
    Log("  .band       = ", c.band);
    Log("  .callsign   = ", c.callsign);
    Log("  .channel    = ", c.channel);
    Log("  .correction = ", c.correction);
    LogNNL("}");
}

inline void Log(const Configuration &c)
{
    LogNNL(c);
    LogNL();
}
```
